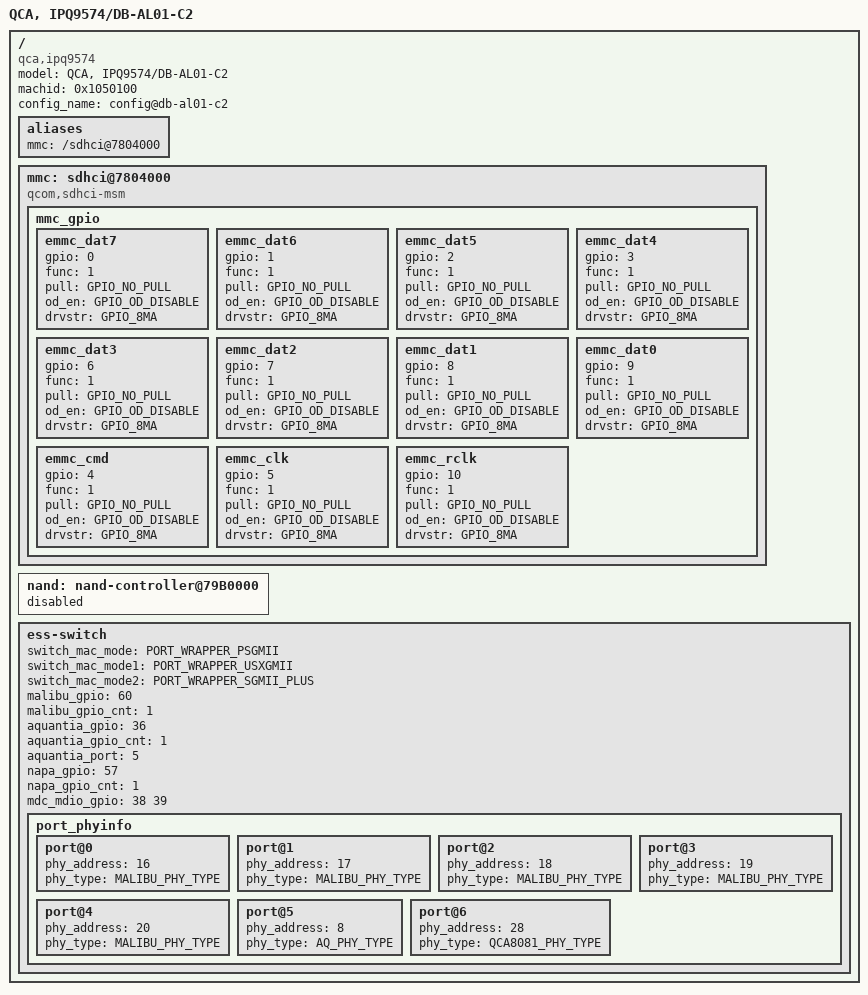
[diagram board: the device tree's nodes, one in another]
/*
 * Copyright (c) 2016-2021, The Linux Foundation. All rights reserved.
 *
 * This program is free software; you can redistribute it and/or modify
 * it under the terms of the GNU General Public License version 2 and
 * only version 2 as published by the Free Software Foundation.
 *
 * This program is distributed in the hope that it will be useful,
 * but WITHOUT ANY WARRANTY; without even the implied warranty of
 * MERCHANTABILITY or FITNESS FOR A PARTICULAR PURPOSE.  See the
 * GNU General Public License for more details.
 */

/dts-v1/;
#include "ipq9574-db-al01-c1.dts"
/ {
	model ="QCA, IPQ9574/DB-AL01-C2";
	compatible = "qca,ipq9574", "qca,ipq9574-db-al01-c2";
	machid = <0x1050100>;
	config_name = "config@db-al01-c2";

	aliases {
		mmc = "/sdhci@7804000";
	};

	mmc: sdhci@7804000 {
		compatible = "qcom,sdhci-msm";
		status = "okay";
		mmc_gpio {
			emmc_dat7 {
				gpio = <0>;
				func = <1>;
				pull = <GPIO_NO_PULL>;
				od_en = <GPIO_OD_DISABLE>;
				drvstr = <GPIO_8MA>;
			};
			emmc_dat6 {
				gpio = <1>;
				func = <1>;
				pull = <GPIO_NO_PULL>;
				od_en = <GPIO_OD_DISABLE>;
				drvstr = <GPIO_8MA>;
			};
			emmc_dat5 {
				gpio = <2>;
				func = <1>;
				pull = <GPIO_NO_PULL>;
				od_en = <GPIO_OD_DISABLE>;
				drvstr = <GPIO_8MA>;
			};
			emmc_dat4 {
				gpio = <3>;
				func = <1>;
				pull = <GPIO_NO_PULL>;
				od_en = <GPIO_OD_DISABLE>;
				drvstr = <GPIO_8MA>;
			};
			emmc_dat3 {
				gpio = <6>;
				func = <1>;
				pull = <GPIO_NO_PULL>;
				od_en = <GPIO_OD_DISABLE>;
				drvstr = <GPIO_8MA>;
			};
			emmc_dat2 {
				gpio = <7>;
				func = <1>;
				pull = <GPIO_NO_PULL>;
				od_en = <GPIO_OD_DISABLE>;
				drvstr = <GPIO_8MA>;
			};
			emmc_dat1 {
				gpio = <8>;
				func = <1>;
				pull = <GPIO_NO_PULL>;
				od_en = <GPIO_OD_DISABLE>;
				drvstr = <GPIO_8MA>;
			};
			emmc_dat0 {
				gpio = <9>;
				func = <1>;
				pull = <GPIO_NO_PULL>;
				od_en = <GPIO_OD_DISABLE>;
				drvstr = <GPIO_8MA>;
			};
			emmc_cmd{
				gpio = <4>;
				func = <1>;
				pull = <GPIO_NO_PULL>;
				od_en = <GPIO_OD_DISABLE>;
				drvstr = <GPIO_8MA>;
			};
			emmc_clk{
				gpio = <5>;
				func = <1>;
				pull = <GPIO_NO_PULL>;
				od_en = <GPIO_OD_DISABLE>;
				drvstr = <GPIO_8MA>;
			};
			emmc_rclk{
				gpio = <10>;
				func = <1>;
				pull = <GPIO_NO_PULL>;
				od_en = <GPIO_OD_DISABLE>;
				drvstr = <GPIO_8MA>;
			};
		};
	};

	nand: nand-controller@79B0000 {
		status = "disabled";
	};

	ess-switch {
		switch_mac_mode = <PORT_WRAPPER_PSGMII>;
		switch_mac_mode1 = <PORT_WRAPPER_USXGMII>;
		switch_mac_mode2 = <PORT_WRAPPER_SGMII_PLUS>;
		malibu_gpio = <60>;
		malibu_gpio_cnt = <1>;
		aquantia_gpio = <36>;
		aquantia_gpio_cnt = <1>;
		aquantia_port = <5>;
		napa_gpio = <57>;
		napa_gpio_cnt = <1>;
		mdc_mdio_gpio = <38 39>;
		port_phyinfo {
			port@0 {
				phy_address = <16>;
				phy_type = <MALIBU_PHY_TYPE>;
			};
			port@1 {
				phy_address = <17>;
				phy_type = <MALIBU_PHY_TYPE>;
			};
			port@2 {
				phy_address = <18>;
				phy_type = <MALIBU_PHY_TYPE>;
			};
			port@3 {
				phy_address = <19>;
				phy_type = <MALIBU_PHY_TYPE>;
			};
			port@4 {
				phy_address = <20>;
				phy_type = <MALIBU_PHY_TYPE>;
			};
			port@5 {
				phy_address = <8>;
				phy_type = <AQ_PHY_TYPE>;
			};
			port@6 {
				phy_address = <28>;
				phy_type = <QCA8081_PHY_TYPE>;
			};
		};
	};
};
